AUTOSAR XML (schema 4.0)
standard types defined: float32, float64, sint16, sint32, sint8, uint16, uint32, uint8, void, boolean
package /ImplDataTypes
  impl type Impl_StepMotorStepType: implementation-data-type=uint8, type-emitter=RTE
package /MappingSets
  data type mapping set MappingSet
package /PortInterfaces/ClientServer
  client server interface CsIf_StepMotor
    operation Opr_Move
      arg step: type=Impl_StepMotorStepType, direction=IN
package /SoftwareComponents
  4 x swc implementation, all with programming-language=C, sw-version=1.0.0, vendor-id=255:
    Impl_SWC_HeightMotor: behavior=Ibhv_SWC_HeightMotor
      code-descriptors:
        code Code: artifact-descriptors=autosar-engineering-object={short-label=SWC.c, category=SWSRC}
      resource consumption ResourceConsumption
    Impl_SWC_SeatManager: behavior=Ibhv_SWC_SeatManager
      code-descriptors:
        code Code: artifact-descriptors=autosar-engineering-object={short-label=SWC.c, category=SWSRC}
      resource consumption ResourceConsumption
    Impl_SWC_inclinemotor: behavior=Ibhv_SWC_inclinemotor
      code-descriptors:
        code Code: artifact-descriptors=autosar-engineering-object={short-label=SWC.c, category=SWSRC}
      resource consumption ResourceConsumption
    Impl_SWC_slidemotor: behavior=Ibhv_SWC_slidemotor
      code-descriptors:
        code Code: artifact-descriptors=autosar-engineering-object={short-label=SWC.c, category=SWSRC}
      resource consumption ResourceConsumption
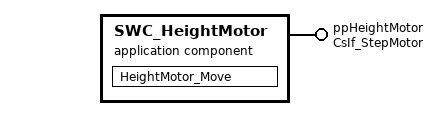
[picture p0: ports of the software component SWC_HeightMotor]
  application sw component type SWC_HeightMotor
    provide port ppHeightMotor: provided-interface=CsIf_StepMotor
    behavior Ibhv_SWC_HeightMotor: data-type-mapping=MappingSet, handle-termination-and-restart=NO-SUPPORT
      operation invoked event OIE_ppHeightMotor_Opr_Move: start-on-event=HeightMotor_Move, operation=ppHeightMotor.Opr_Move
      runnable HeightMotor_Move
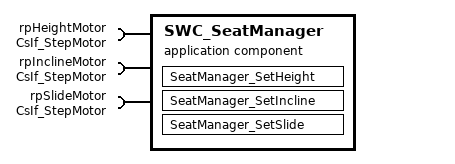
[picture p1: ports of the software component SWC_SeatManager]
  application sw component type SWC_SeatManager
    require port rpHeightMotor: required-interface=CsIf_StepMotor
    require port rpInclineMotor: required-interface=CsIf_StepMotor
    require port rpSlideMotor: required-interface=CsIf_StepMotor
    behavior Ibhv_SWC_SeatManager: data-type-mapping=MappingSet, handle-termination-and-restart=NO-SUPPORT
      runnable SeatManager_SetHeight
        sync call SCP_rpHeightMotor_Opr_Move: operation=rpHeightMotor.Opr_Move, timeout=0.0
      runnable SeatManager_SetIncline
        sync call SCP_rpInclineMotor_Opr_Move: operation=rpInclineMotor.Opr_Move, timeout=0.0
      runnable SeatManager_SetSlide
        sync call SCP_rpSlideMotor_Opr_Move: operation=rpSlideMotor.Opr_Move, timeout=0.0
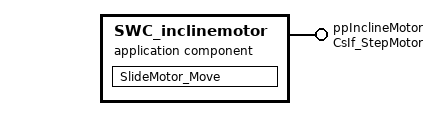
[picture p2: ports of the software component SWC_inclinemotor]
  application sw component type SWC_inclinemotor
    provide port ppInclineMotor: provided-interface=CsIf_StepMotor
    behavior Ibhv_SWC_inclinemotor: data-type-mapping=MappingSet, handle-termination-and-restart=NO-SUPPORT
      operation invoked event OIE_ppInclineMotor_Opr_Move: start-on-event=SlideMotor_Move, operation=ppInclineMotor.Opr_Move
      runnable SlideMotor_Move
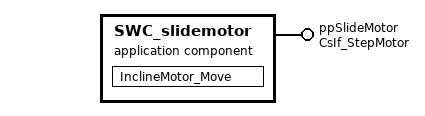
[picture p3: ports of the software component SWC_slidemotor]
  application sw component type SWC_slidemotor
    provide port ppSlideMotor: provided-interface=CsIf_StepMotor
    behavior Ibhv_SWC_slidemotor: data-type-mapping=MappingSet, handle-termination-and-restart=NO-SUPPORT
      operation invoked event OIE_ppSlideMotor_Opr_Move: start-on-event=InclineMotor_Move, operation=ppSlideMotor.Opr_Move
      runnable InclineMotor_Move
package /Compositions
  composition sw component type Client-Server PART1Composition
    4 x component:
      SWC_HeightMotor: type=SWC_HeightMotor
      SWC_SeatManager: type=SWC_SeatManager
      SWC_inclinemotor: type=SWC_inclinemotor
      SWC_slidemotor: type=SWC_slidemotor
    connect SWC_HeightMotor.ppHeightMotor -> SWC_SeatManager.rpHeightMotor
    connect SWC_inclinemotor.ppInclineMotor -> SWC_SeatManager.rpInclineMotor
    connect SWC_slidemotor.ppSlideMotor -> SWC_SeatManager.rpSlideMotor
